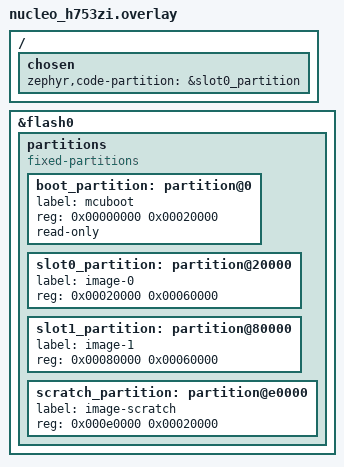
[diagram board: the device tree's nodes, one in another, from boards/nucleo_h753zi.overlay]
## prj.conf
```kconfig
CONFIG_GPIO=y

CONFIG_BOOTLOADER_MCUBOOT=y
CONFIG_MCUBOOT_SIGNATURE_KEY_FILE="/bootloader/mcuboot/root-ec-p256.pem"

CONFIG_MCUBOOT_IMGTOOL_SIGN_VERSION="5.3.0"
# CONFIG_MCUBOOT_EXTRA_IMGTOOL_ARGS="--confirm"
```

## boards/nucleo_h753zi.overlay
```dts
/delete-node/ &boot_partition;
/delete-node/ &slot0_partition;
/delete-node/ &slot1_partition;
/delete-node/ &scratch_partition;

&flash0 {
    partitions {
        compatible = "fixed-partitions";
        #address-cells = <1>;
        #size-cells = <1>;

        boot_partition: partition@0 {
            label = "mcuboot";
            reg = <0x00000000 0x00020000>;  /* 128KB */
            read-only;
        };

        slot0_partition: partition@20000 {
            label = "image-0";
            reg = <0x00020000 0x00060000>;  /* 384KB */
        };

        slot1_partition: partition@80000 {
            label = "image-1";
            reg = <0x00080000 0x00060000>;  /* 384KB */
        };

        scratch_partition: partition@e0000 {
            label = "image-scratch";
            reg = <0x000e0000 0x00020000>;  /* 128KB */
        };
    };
};

/ {
    chosen {
        zephyr,code-partition = &slot0_partition;
    };
};
```

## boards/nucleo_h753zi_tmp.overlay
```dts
&flash0 {
    partitions {
        compatible = "fixed-partitions";
        #address-cells = <1>;
        #size-cells = <1>;

        boot_partition: partition@0 {
            label = "mcuboot";
            reg = <0x00000000 DT_SIZE_K(128)>;
        };

        slot0_partition: partition@20000 {
            label = "image-0";
            reg = <0x00020000 DT_SIZE_K(384)>;
        };

        slot1_partition: partition@80000 {
            label = "image-1";
            reg = <0x00080000 DT_SIZE_K(384)>;
        };

        scratch_partition: partition@e0000 {
            label = "image-scratch";
            reg = <0x000e0000 DT_SIZE_K(128)>;
        };
    };
};

/ {
    chosen {
        zephyr,code-partition = &slot0_partition;
    };
};
```

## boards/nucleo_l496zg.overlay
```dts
&flash0 {
    partitions {
        compatible = "fixed-partitions";
        #address-cells = <1>;
        #size-cells = <1>;

        boot_partition: partition@0 {
            label = "mcuboot";
            reg = <0x00000000 0x00020000>;  /* 128KB */
            read-only;
        };

        slot0_partition: partition@20000 {
            label = "image-0";
            reg = <0x00020000 0x00060000>;  /* 384KB */
        };

        slot1_partition: partition@80000 {
            label = "image-1";
            reg = <0x00080000 0x00060000>;  /* 384KB */
        };
    };
};

/ {
    chosen {
        zephyr,code-partition = &slot1_partition;
    };
};
```

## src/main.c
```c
/*
 * Copyright (c) 2016 Intel Corporation
 *
 * SPDX-License-Identifier: Apache-2.0
 */

#include <stdio.h>
#include <zephyr/kernel.h>
#include <zephyr/drivers/gpio.h>

/* 1000 msec = 1 sec */
#define SLEEP_TIME_MS   1000

/* The devicetree node identifier for the "led0" alias. */
#define LED0_NODE DT_ALIAS(led0)

/*
 * A build error on this line means your board is unsupported.
 * See the sample documentation for information on how to fix this.
 */
static const struct gpio_dt_spec led = GPIO_DT_SPEC_GET(LED0_NODE, gpios);

int main(void)
{
	printf("hello world");
	int ret;
	bool led_state = true;

	if (!gpio_is_ready_dt(&led)) {
		return 0;
	}

	ret = gpio_pin_configure_dt(&led, GPIO_OUTPUT_ACTIVE);
	if (ret < 0) {
		return 0;
	}

	while (1) {
		ret = gpio_pin_toggle_dt(&led);
		if (ret < 0) {
			return 0;
		}

		led_state = !led_state;
		printf("LED state: %s\n", led_state ? "ON" : "OFF");
		k_msleep(SLEEP_TIME_MS);
	}
	return 0;
}
```
